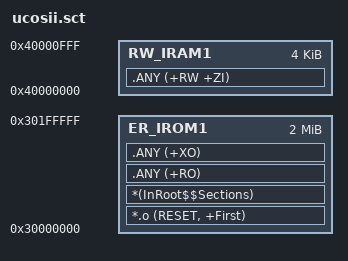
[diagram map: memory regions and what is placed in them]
; *************************************************************
; *** Scatter-Loading Description File generated by uVision ***
; *************************************************************

LR_IROM1 0x00000000 0x00200000  {    ; Load region at 0x00000000 (NOR/boot)
  ER_IROM1 0x30000000 0x00200000  {  ; Execute from SDRAM at 0x30000000
   *.o (RESET, +First)
   *(InRoot$$Sections)
   .ANY (+RO)
   .ANY (+XO)
  }
  RW_IRAM1 0x40000000 0x00001000  {  ; RW data
   .ANY (+RW +ZI)
  }
}

